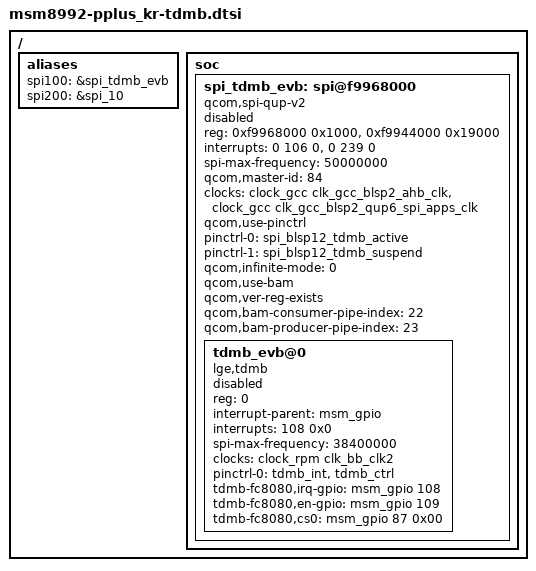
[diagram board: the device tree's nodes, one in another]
/* Copyright (c) 2014, The Linux Foundation. All rights reserved.
 *
 * This program is free software; you can redistribute it and/or modify
 * it under the terms of the GNU General Public License version 2 and
 * only version 2 as published by the Free Software Foundation.
 *
 * This program is distributed in the hope that it will be useful,
 * but WITHOUT ANY WARRANTY; without even the implied warranty of
 * MERCHANTABILITY or FITNESS FOR A PARTICULAR PURPOSE.  See the
 * GNU General Public License for more details.
 */

/ {
    aliases {
        spi100 = &spi_tdmb_evb;
        spi200 = &spi_10;
    };
    soc {
        spi_tdmb_evb: spi@f9968000{    /*BLSP-2 QUP5 */
            status = "disable";
            compatible = "qcom,spi-qup-v2";

            #address-cells = <1>;
            #size-cells = <0>;

            reg-names = "spi_physical", "spi_bam_physical";
            reg = <0xf9968000 0x1000>, <0xf9944000 0x19000>;

            interrupt-names = "spi_irq", "spi_bam_irq";
            interrupts = <0 106 0>, <0 239 0>;

            spi-max-frequency = <50000000>;

            qcom,master-id = <84>; //Keep AHB clocks ON
            clock-names = "iface_clk", "core_clk";
            clocks = <&clock_gcc clk_gcc_blsp2_ahb_clk>,
                <&clock_gcc clk_gcc_blsp2_qup6_spi_apps_clk>;

            /* Assign runtime functions to pins */
            qcom,use-pinctrl;
            pinctrl-names = "spi_default","spi_sleep";
            pinctrl-0 = <&spi_blsp12_tdmb_active>;
            pinctrl-1 = <&spi_blsp12_tdmb_suspend>;
/*
            qcom,gpio-mosi = <&msm_gpio 85 0>;
            qcom,gpio-miso = <&msm_gpio 86 0>;
            qcom,gpio-cs0 = <&msm_gpio 87 0>;
            qcom,gpio-clk = <&msm_gpio 88 0>;
*/
            qcom,infinite-mode = <0>;
            qcom,use-bam;
            qcom,ver-reg-exists;
            qcom,bam-consumer-pipe-index = <22>;
            qcom,bam-producer-pipe-index = <23>;
        };
    };
/*
    soc {
        spi_tdmb_rev: spi@f9966000{    
            status = "disable";
            compatible = "qcom,spi-qup-v2";

            #address-cells = <1>;
            #size-cells = <0>;

            reg-names = "spi_physical", "spi_bam_physical";
            reg = <0xf9966000 0x1000>, <0xf9944000 0x19000>;

            interrupt-names = "spi_irq", "spi_bam_irq";
            interrupts = <0 104 0>, <0 239 0>;

            spi-max-frequency = <15000000>;

            qcom,master-id = <84>; //Keep AHB clocks ON
            clock-names = "iface_clk", "core_clk";
            clocks = <&clock_gcc clk_gcc_blsp2_ahb_clk>,
                <&clock_gcc clk_gcc_blsp2_qup4_spi_apps_clk>;

           
            qcom,use-pinctrl;
            pinctrl-names = "spi_default","spi_sleep";
            pinctrl-0 = <&spi_blsp10_bus_active &spi_blsp10_cs_active>;
            pinctrl-1 = <&spi_blsp10_bus_suspend &spi_blsp10_cs_suspend>;

            qcom,infinite-mode = <0>;
            qcom,use-bam;
            qcom,ver-reg-exists;
            qcom,bam-consumer-pipe-index = <18>;
            qcom,bam-producer-pipe-index = <19>;
        };
    };*/
};

&spi_tdmb_evb {
    tdmb_evb@0 {
        status = "disable";
        compatible = "lge,tdmb";
        reg = <0>;
        interrupt-parent = <&msm_gpio>;
        interrupts = <108 0x0>;
        spi-max-frequency = <38400000>;

        /* TDMB CLK */
        clock-names = "tdmb_xo";
        clocks = <&clock_rpm clk_bb_clk2>;

        pinctrl-names = "gpio_tdmb_suspend";
        pinctrl-0 = <&tdmb_int &tdmb_ctrl>;
        tdmb-fc8080,irq-gpio = <&msm_gpio 108 0x00>;
        tdmb-fc8080,en-gpio = <&msm_gpio 109 0x00>;
        tdmb-fc8080,cs0 = <&msm_gpio 87 0x00>;
    };
};
/*
&spi_10 {
    tdmb_rev@3 {
        status = "disable";
        compatible = "lge,tdmb";
        reg = <3>;
        interrupt-parent = <&msm_gpio>;
        interrupts = <108 0x0>;
        spi-max-frequency = <15000000>;

        clock-names = "tdmb_xo";
        clocks = <&clock_rpm clk_bb_clk2>;

        pinctrl-names = "gpio_tdmb_suspend";
        pinctrl-0 = <&tdmb_int &tdmb_ctrl>;

        tdmb-fc8080,irq-gpio = <&msm_gpio 108 0x00>;
        tdmb-fc8080,en-gpio = <&msm_gpio 109 0x00>;
        tdmb-fc8080,cs0 = <&msm_gpio 55 0x00>;
        tdmb-fc8080,cs2 = <&msm_gpio 68 0x00>;
        tdmb-fc8080,cs3 = <&msm_gpio 90 0x00>;
    };
};
*/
